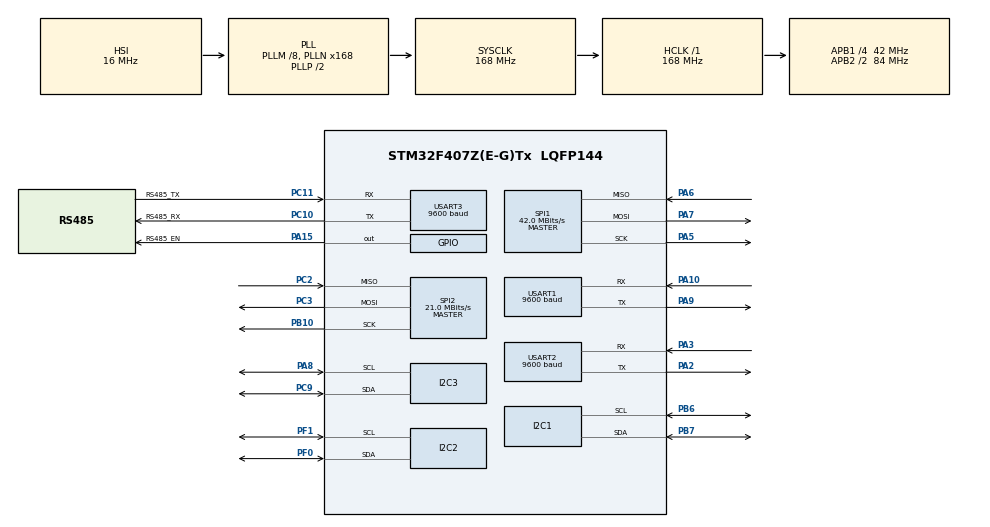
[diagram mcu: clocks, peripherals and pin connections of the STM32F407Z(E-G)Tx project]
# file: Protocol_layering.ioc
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Mcu.Family=STM32F4
Mcu.Name=STM32F407Z(E-G)Tx
Mcu.Package=LQFP144
NVIC.PriorityGroup=NVIC_PRIORITYGROUP_4
NVIC.TIM2_IRQn=true\:0\:0\:false\:false\:true\:true\:true\:true
NVIC.USART1_IRQn=true\:0\:0\:false\:false\:true\:true\:true\:true
NVIC.USART2_IRQn=true\:0\:0\:false\:false\:true\:true\:true\:true
NVIC.USART3_IRQn=true\:0\:0\:false\:false\:true\:true\:true\:true
PA10.Mode=Asynchronous
PA10.Signal=USART1_RX
PA13.Mode=Serial_Wire
PA13.Signal=SYS_JTMS-SWDIO
PA14.Mode=Serial_Wire
PA14.Signal=SYS_JTCK-SWCLK
PA15.GPIO_Label=RS485_EN
PA15.Signal=GPIO_Output
PA2.Mode=Asynchronous
PA2.Signal=USART2_TX
PA3.Mode=Asynchronous
PA3.Signal=USART2_RX
PA5.Mode=Full_Duplex_Master
PA5.Signal=SPI1_SCK
PA6.Mode=Full_Duplex_Master
PA6.Signal=SPI1_MISO
PA7.Mode=Full_Duplex_Master
PA7.Signal=SPI1_MOSI
PA8.Mode=I2C
PA8.Signal=I2C3_SCL
PA9.Mode=Asynchronous
PA9.Signal=USART1_TX
PB10.Mode=Full_Duplex_Master
PB10.Signal=SPI2_SCK
PB6.Mode=I2C
PB6.Signal=I2C1_SCL
PB7.Mode=I2C
PB7.Signal=I2C1_SDA
PC10.GPIO_Label=RS485_RX
PC10.Mode=Asynchronous
PC10.Signal=USART3_TX
PC11.GPIO_Label=RS485_TX
PC11.Mode=Asynchronous
PC11.Signal=USART3_RX
PC2.Mode=Full_Duplex_Master
PC2.Signal=SPI2_MISO
PC3.Mode=Full_Duplex_Master
PC3.Signal=SPI2_MOSI
PC9.Mode=I2C
PC9.Signal=I2C3_SDA
PF0.Mode=I2C
PF0.Signal=I2C2_SDA
PF1.Mode=I2C
PF1.Signal=I2C2_SCL
PH0-OSC_IN.Mode=HSE-External-Oscillator
PH0-OSC_IN.Signal=RCC_OSC_IN
PH1-OSC_OUT.Mode=HSE-External-Oscillator
PH1-OSC_OUT.Signal=RCC_OSC_OUT
ProjectManager.HeapSize=0x200
ProjectManager.StackSize=0x400
ProjectManager.TargetToolchain=STM32CubeIDE
RCC.48MHZClocksFreq_Value=84000000
RCC.AHBFreq_Value=168000000
RCC.APB1CLKDivider=RCC_HCLK_DIV4
RCC.APB1Freq_Value=42000000
RCC.APB1TimFreq_Value=84000000
RCC.APB2CLKDivider=RCC_HCLK_DIV2
RCC.APB2Freq_Value=84000000
RCC.APB2TimFreq_Value=168000000
RCC.CortexFreq_Value=168000000
RCC.HCLKFreq_Value=168000000
RCC.HSE_VALUE=8000000
RCC.HSI_VALUE=16000000
RCC.LSE_VALUE=32768
RCC.PLLM=8
RCC.PLLN=168
RCC.SYSCLKFreq_VALUE=168000000
RCC.SYSCLKSource=RCC_SYSCLKSOURCE_PLLCLK
RCC.VCOOutputFreq_Value=336000000
SPI1.CalculateBaudRate=42.0 MBits/s
SPI1.Direction=SPI_DIRECTION_2LINES
SPI1.Mode=SPI_MODE_MASTER
SPI1.VirtualType=VM_MASTER
SPI2.CalculateBaudRate=21.0 MBits/s
SPI2.Direction=SPI_DIRECTION_2LINES
SPI2.Mode=SPI_MODE_MASTER
SPI2.VirtualType=VM_MASTER
TIM2.Period=9
TIM2.Prescaler=8399
USART1.BaudRate=9600
USART1.VirtualMode=VM_ASYNC
USART2.BaudRate=9600
USART2.VirtualMode=VM_ASYNC
USART3.BaudRate=9600
USART3.VirtualMode=VM_ASYNC
VP_TIM2_VS_ClockSourceINT.Mode=Internal
board=custom

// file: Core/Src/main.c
/* USER CODE BEGIN Header */
/**
  ******************************************************************************
  * @file           : main.c
  * @brief          : Main program body
  ******************************************************************************
  * @attention
  *
  * Copyright (c) 2025 STMicroelectronics.
  * All rights reserved.
  *
  * This software is licensed under terms that can be found in the LICENSE file
  * in the root directory of this software component.
  * If no LICENSE file comes with this software, it is provided AS-IS.
  *
  ******************************************************************************
  */
/* USER CODE END Header */
#include "main.h"

/* USER CODE BEGIN Includes */
#include "EncryptDecrypt.h"
/* USER CODE END Includes */

I2C_HandleTypeDef hi2c1;
I2C_HandleTypeDef hi2c2;
I2C_HandleTypeDef hi2c3;

SPI_HandleTypeDef hspi1;
SPI_HandleTypeDef hspi2;

TIM_HandleTypeDef htim2;

UART_HandleTypeDef huart1;
UART_HandleTypeDef huart2;
UART_HandleTypeDef huart3;

void SystemClock_Config(void);
static void MX_GPIO_Init(void);
static void MX_I2C1_Init(void);
static void MX_I2C2_Init(void);
static void MX_I2C3_Init(void);
static void MX_SPI1_Init(void);
static void MX_SPI2_Init(void);
static void MX_TIM2_Init(void);
static void MX_USART2_UART_Init(void);
static void MX_USART3_UART_Init(void);
static void MX_USART1_UART_Init(void);

int main(void)
{

  /* MCU Configuration--------------------------------------------------------*/

  /* Reset of all peripherals, Initializes the Flash interface and the Systick. */
  HAL_Init();

  /* Configure the system clock */
  SystemClock_Config();

  /* Initialize all configured peripherals */
  MX_GPIO_Init();
  MX_I2C1_Init();
  MX_I2C2_Init();
  MX_I2C3_Init();
  MX_SPI1_Init();
  MX_SPI2_Init();
  MX_TIM2_Init();
  MX_USART2_UART_Init();
  MX_USART3_UART_Init();
  MX_USART1_UART_Init();

  /* Infinite loop */
  while (1)
  {

  }
}

void SystemClock_Config(void)
{
  RCC_OscInitTypeDef RCC_OscInitStruct = {0};
  RCC_ClkInitTypeDef RCC_ClkInitStruct = {0};

  /** Configure the main internal regulator output voltage
  */
  __HAL_RCC_PWR_CLK_ENABLE();
  __HAL_PWR_VOLTAGESCALING_CONFIG(PWR_REGULATOR_VOLTAGE_SCALE1);

  /** Initializes the RCC Oscillators according to the specified parameters
  * in the RCC_OscInitTypeDef structure.
  */
  RCC_OscInitStruct.OscillatorType = RCC_OSCILLATORTYPE_HSI;
  RCC_OscInitStruct.HSIState = RCC_HSI_ON;
  RCC_OscInitStruct.HSICalibrationValue = RCC_HSICALIBRATION_DEFAULT;
  RCC_OscInitStruct.PLL.PLLState = RCC_PLL_ON;
  RCC_OscInitStruct.PLL.PLLSource = RCC_PLLSOURCE_HSI;
  RCC_OscInitStruct.PLL.PLLM = 8;
  RCC_OscInitStruct.PLL.PLLN = 168;
  RCC_OscInitStruct.PLL.PLLP = RCC_PLLP_DIV2;
  RCC_OscInitStruct.PLL.PLLQ = 4;
  if (HAL_RCC_OscConfig(&RCC_OscInitStruct) != HAL_OK)
  {
    Error_Handler();
  }

  /** Initializes the CPU, AHB and APB buses clocks
  */
  RCC_ClkInitStruct.ClockType = RCC_CLOCKTYPE_HCLK|RCC_CLOCKTYPE_SYSCLK
                              |RCC_CLOCKTYPE_PCLK1|RCC_CLOCKTYPE_PCLK2;
  RCC_ClkInitStruct.SYSCLKSource = RCC_SYSCLKSOURCE_PLLCLK;
  RCC_ClkInitStruct.AHBCLKDivider = RCC_SYSCLK_DIV1;
  RCC_ClkInitStruct.APB1CLKDivider = RCC_HCLK_DIV4;
  RCC_ClkInitStruct.APB2CLKDivider = RCC_HCLK_DIV2;

  if (HAL_RCC_ClockConfig(&RCC_ClkInitStruct, FLASH_LATENCY_5) != HAL_OK)
  {
    Error_Handler();
  }
}

static void MX_I2C1_Init(void)
{

  hi2c1.Instance = I2C1;
  hi2c1.Init.ClockSpeed = 100000;
  hi2c1.Init.DutyCycle = I2C_DUTYCYCLE_2;
  hi2c1.Init.OwnAddress1 = 0;
  hi2c1.Init.AddressingMode = I2C_ADDRESSINGMODE_7BIT;
  hi2c1.Init.DualAddressMode = I2C_DUALADDRESS_DISABLE;
  hi2c1.Init.OwnAddress2 = 0;
  hi2c1.Init.GeneralCallMode = I2C_GENERALCALL_DISABLE;
  hi2c1.Init.NoStretchMode = I2C_NOSTRETCH_DISABLE;
  if (HAL_I2C_Init(&hi2c1) != HAL_OK)
  {
    Error_Handler();
  }

}

static void MX_I2C2_Init(void)
{

  hi2c2.Instance = I2C2;
  hi2c2.Init.ClockSpeed = 100000;
  hi2c2.Init.DutyCycle = I2C_DUTYCYCLE_2;
  hi2c2.Init.OwnAddress1 = 0;
  hi2c2.Init.AddressingMode = I2C_ADDRESSINGMODE_7BIT;
  hi2c2.Init.DualAddressMode = I2C_DUALADDRESS_DISABLE;
  hi2c2.Init.OwnAddress2 = 0;
  hi2c2.Init.GeneralCallMode = I2C_GENERALCALL_DISABLE;
  hi2c2.Init.NoStretchMode = I2C_NOSTRETCH_DISABLE;
  if (HAL_I2C_Init(&hi2c2) != HAL_OK)
  {
    Error_Handler();
  }

}

static void MX_I2C3_Init(void)
{

  hi2c3.Instance = I2C3;
  hi2c3.Init.ClockSpeed = 100000;
  hi2c3.Init.DutyCycle = I2C_DUTYCYCLE_2;
  hi2c3.Init.OwnAddress1 = 0;
  hi2c3.Init.AddressingMode = I2C_ADDRESSINGMODE_7BIT;
  hi2c3.Init.DualAddressMode = I2C_DUALADDRESS_DISABLE;
  hi2c3.Init.OwnAddress2 = 0;
  hi2c3.Init.GeneralCallMode = I2C_GENERALCALL_DISABLE;
  hi2c3.Init.NoStretchMode = I2C_NOSTRETCH_DISABLE;
  if (HAL_I2C_Init(&hi2c3) != HAL_OK)
  {
    Error_Handler();
  }

}

static void MX_SPI1_Init(void)
{

  /* SPI1 parameter configuration*/
  hspi1.Instance = SPI1;
  hspi1.Init.Mode = SPI_MODE_MASTER;
  hspi1.Init.Direction = SPI_DIRECTION_2LINES;
  hspi1.Init.DataSize = SPI_DATASIZE_8BIT;
  hspi1.Init.CLKPolarity = SPI_POLARITY_LOW;
  hspi1.Init.CLKPhase = SPI_PHASE_1EDGE;
  hspi1.Init.NSS = SPI_NSS_SOFT;
  hspi1.Init.BaudRatePrescaler = SPI_BAUDRATEPRESCALER_2;
  hspi1.Init.FirstBit = SPI_FIRSTBIT_MSB;
  hspi1.Init.TIMode = SPI_TIMODE_DISABLE;
  hspi1.Init.CRCCalculation = SPI_CRCCALCULATION_DISABLE;
  hspi1.Init.CRCPolynomial = 10;
  if (HAL_SPI_Init(&hspi1) != HAL_OK)
  {
    Error_Handler();
  }

}

static void MX_SPI2_Init(void)
{

  /* SPI2 parameter configuration*/
  hspi2.Instance = SPI2;
  hspi2.Init.Mode = SPI_MODE_MASTER;
  hspi2.Init.Direction = SPI_DIRECTION_2LINES;
  hspi2.Init.DataSize = SPI_DATASIZE_8BIT;
  hspi2.Init.CLKPolarity = SPI_POLARITY_LOW;
  hspi2.Init.CLKPhase = SPI_PHASE_1EDGE;
  hspi2.Init.NSS = SPI_NSS_SOFT;
  hspi2.Init.BaudRatePrescaler = SPI_BAUDRATEPRESCALER_2;
  hspi2.Init.FirstBit = SPI_FIRSTBIT_MSB;
  hspi2.Init.TIMode = SPI_TIMODE_DISABLE;
  hspi2.Init.CRCCalculation = SPI_CRCCALCULATION_DISABLE;
  hspi2.Init.CRCPolynomial = 10;
  if (HAL_SPI_Init(&hspi2) != HAL_OK)
  {
    Error_Handler();
  }

}

static void MX_TIM2_Init(void)
{

  TIM_ClockConfigTypeDef sClockSourceConfig = {0};
  TIM_MasterConfigTypeDef sMasterConfig = {0};

  htim2.Instance = TIM2;
  htim2.Init.Prescaler = 8399;
  htim2.Init.CounterMode = TIM_COUNTERMODE_UP;
  htim2.Init.Period = 9;
  htim2.Init.ClockDivision = TIM_CLOCKDIVISION_DIV1;
  htim2.Init.AutoReloadPreload = TIM_AUTORELOAD_PRELOAD_DISABLE;
  if (HAL_TIM_Base_Init(&htim2) != HAL_OK)
  {
    Error_Handler();
  }
  sClockSourceConfig.ClockSource = TIM_CLOCKSOURCE_INTERNAL;
  if (HAL_TIM_ConfigClockSource(&htim2, &sClockSourceConfig) != HAL_OK)
  {
    Error_Handler();
  }
  sMasterConfig.MasterOutputTrigger = TIM_TRGO_RESET;
  sMasterConfig.MasterSlaveMode = TIM_MASTERSLAVEMODE_DISABLE;
  if (HAL_TIMEx_MasterConfigSynchronization(&htim2, &sMasterConfig) != HAL_OK)
  {
    Error_Handler();
  }

}

static void MX_USART1_UART_Init(void)
{

  huart1.Instance = USART1;
  huart1.Init.BaudRate = 9600;
  huart1.Init.WordLength = UART_WORDLENGTH_8B;
  huart1.Init.StopBits = UART_STOPBITS_1;
  huart1.Init.Parity = UART_PARITY_NONE;
  huart1.Init.Mode = UART_MODE_TX_RX;
  huart1.Init.HwFlowCtl = UART_HWCONTROL_NONE;
  huart1.Init.OverSampling = UART_OVERSAMPLING_16;
  if (HAL_UART_Init(&huart1) != HAL_OK)
  {
    Error_Handler();
  }

}

static void MX_USART2_UART_Init(void)
{

  huart2.Instance = USART2;
  huart2.Init.BaudRate = 9600;
  huart2.Init.WordLength = UART_WORDLENGTH_8B;
  huart2.Init.StopBits = UART_STOPBITS_1;
  huart2.Init.Parity = UART_PARITY_NONE;
  huart2.Init.Mode = UART_MODE_TX_RX;
  huart2.Init.HwFlowCtl = UART_HWCONTROL_NONE;
  huart2.Init.OverSampling = UART_OVERSAMPLING_16;
  if (HAL_UART_Init(&huart2) != HAL_OK)
  {
    Error_Handler();
  }

}

static void MX_USART3_UART_Init(void)
{

  huart3.Instance = USART3;
  huart3.Init.BaudRate = 9600;
  huart3.Init.WordLength = UART_WORDLENGTH_8B;
  huart3.Init.StopBits = UART_STOPBITS_1;
  huart3.Init.Parity = UART_PARITY_NONE;
  huart3.Init.Mode = UART_MODE_TX_RX;
  huart3.Init.HwFlowCtl = UART_HWCONTROL_NONE;
  huart3.Init.OverSampling = UART_OVERSAMPLING_16;
  if (HAL_UART_Init(&huart3) != HAL_OK)
  {
    Error_Handler();
  }

}

static void MX_GPIO_Init(void)
{
  GPIO_InitTypeDef GPIO_InitStruct = {0};

  /* GPIO Ports Clock Enable */
  __HAL_RCC_GPIOF_CLK_ENABLE();
  __HAL_RCC_GPIOH_CLK_ENABLE();
  __HAL_RCC_GPIOC_CLK_ENABLE();
  __HAL_RCC_GPIOA_CLK_ENABLE();
  __HAL_RCC_GPIOB_CLK_ENABLE();

  /*Configure GPIO pin Output Level */
  HAL_GPIO_WritePin(RS485_EN_GPIO_Port, RS485_EN_Pin, GPIO_PIN_RESET);

  /*Configure GPIO pin : RS485_EN_Pin */
  GPIO_InitStruct.Pin = RS485_EN_Pin;
  GPIO_InitStruct.Mode = GPIO_MODE_OUTPUT_PP;
  GPIO_InitStruct.Pull = GPIO_NOPULL;
  GPIO_InitStruct.Speed = GPIO_SPEED_FREQ_LOW;
  HAL_GPIO_Init(RS485_EN_GPIO_Port, &GPIO_InitStruct);

}

void Error_Handler(void)
{
  __disable_irq();
  while (1)
  {
  }
}
